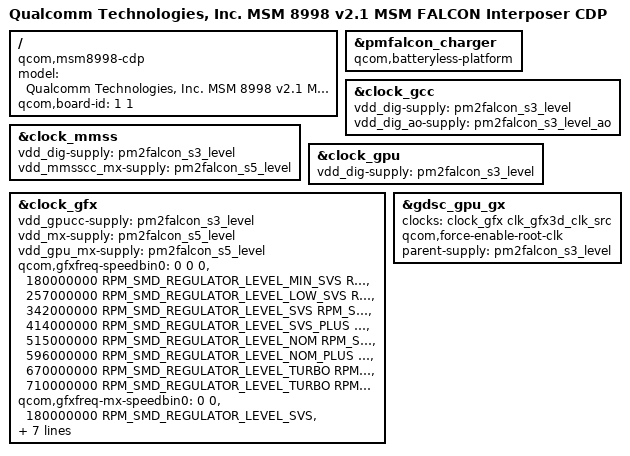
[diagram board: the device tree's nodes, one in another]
/* Copyright (c) 2016, The Linux Foundation. All rights reserved.
 *
 * This program is free software; you can redistribute it and/or modify
 * it under the terms of the GNU General Public License version 2 and
 * only version 2 as published by the Free Software Foundation.
 *
 * This program is distributed in the hope that it will be useful,
 * but WITHOUT ANY WARRANTY; without even the implied warranty of
 * MERCHANTABILITY or FITNESS FOR A PARTICULAR PURPOSE.  See the
 * GNU General Public License for more details.
 */


/dts-v1/;

#include "msm8998-v2.1-interposer-msmfalcon.dtsi"
#include "msm8998-interposer-msmfalcon-cdp.dtsi"
#include "msm8998-interposer-pmfalcon.dtsi"
#include "msm8998-interposer-msmfalcon-audio.dtsi"
#include "msm8998-interposer-camera-sensor-cdp.dtsi"

/ {
	model = "Qualcomm Technologies, Inc. MSM 8998 v2.1 MSM FALCON Interposer CDP";
	compatible = "qcom,msm8998-cdp", "qcom,msm8998", "qcom,cdp";
	qcom,board-id = <1 1>;
};

&pmfalcon_charger {
	qcom,batteryless-platform;
};

&clock_gcc {
	vdd_dig-supply = <&pm2falcon_s3_level>;
	vdd_dig_ao-supply = <&pm2falcon_s3_level_ao>;
};

&clock_mmss {
	vdd_dig-supply = <&pm2falcon_s3_level>;
	vdd_mmsscc_mx-supply = <&pm2falcon_s5_level>;
};

&clock_gpu {
	vdd_dig-supply = <&pm2falcon_s3_level>;
};

&clock_gfx {
	/* GFX Rail = CX */
	vdd_gpucc-supply = <&pm2falcon_s3_level>;
	vdd_mx-supply = <&pm2falcon_s5_level>;
	vdd_gpu_mx-supply = <&pm2falcon_s5_level>;
	qcom,gfxfreq-speedbin0 =
		<         0 0                           0 >,
		< 180000000 RPM_SMD_REGULATOR_LEVEL_MIN_SVS
					RPM_SMD_REGULATOR_LEVEL_SVS >,
		< 257000000 RPM_SMD_REGULATOR_LEVEL_LOW_SVS
					RPM_SMD_REGULATOR_LEVEL_SVS >,
		< 342000000 RPM_SMD_REGULATOR_LEVEL_SVS
					RPM_SMD_REGULATOR_LEVEL_SVS >,
		< 414000000 RPM_SMD_REGULATOR_LEVEL_SVS_PLUS
					RPM_SMD_REGULATOR_LEVEL_SVS >,
		< 515000000 RPM_SMD_REGULATOR_LEVEL_NOM
					RPM_SMD_REGULATOR_LEVEL_NOM >,
		< 596000000 RPM_SMD_REGULATOR_LEVEL_NOM_PLUS
					RPM_SMD_REGULATOR_LEVEL_NOM >,
		< 670000000 RPM_SMD_REGULATOR_LEVEL_TURBO
					RPM_SMD_REGULATOR_LEVEL_TURBO >,
		< 710000000 RPM_SMD_REGULATOR_LEVEL_TURBO
					RPM_SMD_REGULATOR_LEVEL_TURBO >;
	qcom,gfxfreq-mx-speedbin0 =
		<         0                           0 >,
		< 180000000 RPM_SMD_REGULATOR_LEVEL_SVS >,
		< 257000000 RPM_SMD_REGULATOR_LEVEL_SVS >,
		< 342000000 RPM_SMD_REGULATOR_LEVEL_SVS >,
		< 414000000 RPM_SMD_REGULATOR_LEVEL_SVS >,
		< 515000000 RPM_SMD_REGULATOR_LEVEL_NOM >,
		< 596000000 RPM_SMD_REGULATOR_LEVEL_NOM >,
		< 670000000 RPM_SMD_REGULATOR_LEVEL_TURBO >,
		< 710000000 RPM_SMD_REGULATOR_LEVEL_TURBO >;
};

&gdsc_gpu_gx {
	clock-names = "core_root_clk";
	clocks = <&clock_gfx clk_gfx3d_clk_src>;
	qcom,force-enable-root-clk;
	/* GFX Rail = CX */
	parent-supply = <&pm2falcon_s3_level>;
	status = "ok";
};
